# STM32H747xx_CM7 register map
File version: 1.0
Registers are 32-bit, read-write, reset 0x0 unless marked. A register's access mark holds for its fields unless they carry their own. Offsets are from the block's base; [hi:lo] are bit positions; {n}, {i} and the like mark numbered series; 'fields as' and 'values as' point back to an identical list.

## VREFBUF
Base 0x58003C00
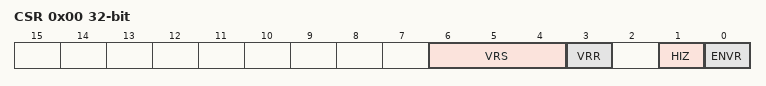
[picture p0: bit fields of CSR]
0x00 CSR — VREFBUF control and status register
  [6:4] VRS — Voltage reference scale
  [3] VRR — Voltage reference buffer ready
  [1] HIZ — High impedance mode
  [0] ENVR — Voltage reference buffer enable
0x04 CCR — VREFBUF calibration and control register
  [5:0] TRIM — TRIM[5:0] bits (Trimming code)

## IWDG1 — Independent WATCHDOG
Base 0x58004800
Same registers: IWDG2 0x58004C00
0x00 KR — IWDG Key register
  [15:0] KEY — Key value (write only, read 0000h)
0x04 PR — IWDG Prescaler register
  [2:0] PR — PR[2:0] (Prescaler divider)
0x08 RLR — IWDG Reload register
  [11:0] RL — Watchdog counter reload value
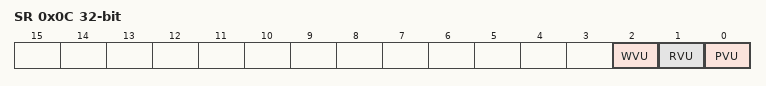
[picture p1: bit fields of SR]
0x0C SR — IWDG Status register
  [2] WVU — Watchdog counter window value update
  [1] RVU — Watchdog counter reload value update
  [0] PVU — Watchdog prescaler value update
0x10 WINR — IWDG Window register
  [11:0] WIN — Watchdog counter window value

## GPIOA — General Purpose I/O
Base 0x58020000
Same registers: GPIOB 0x58020400, GPIOC 0x58020800, GPIOD 0x58020C00, GPIOE 0x58021000, GPIOF 0x58021400, GPIOG 0x58021800, GPIOH 0x58021C00, GPIOI 0x58022000, GPIOJ 0x58022400, GPIOK 0x58022800
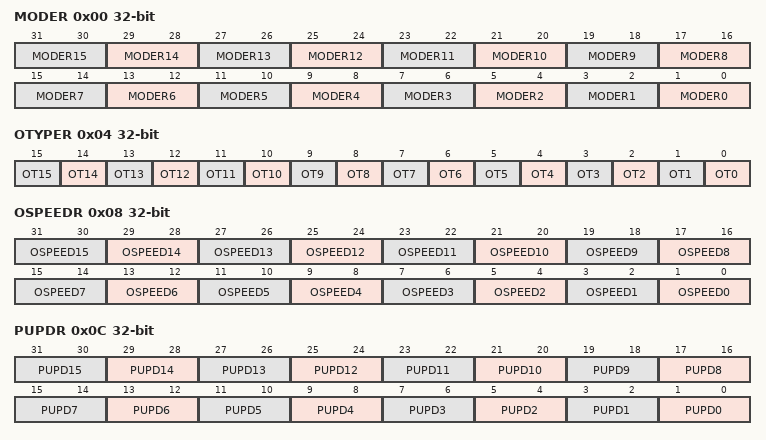
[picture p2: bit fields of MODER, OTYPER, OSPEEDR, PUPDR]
0x00 MODER — GPIO port mode register
  [2n+1:2n] MODER{n} (n=0..15)
0x04 OTYPER — GPIO port output type register
  [n] OT{n} (n=0..15)
0x08 OSPEEDR — GPIO port output speed register
  [2n+1:2n] OSPEED{n} (n=0..15)
0x0C PUPDR — GPIO port pull-up/pull-down register
  [2n+1:2n] PUPD{n} (n=0..15)
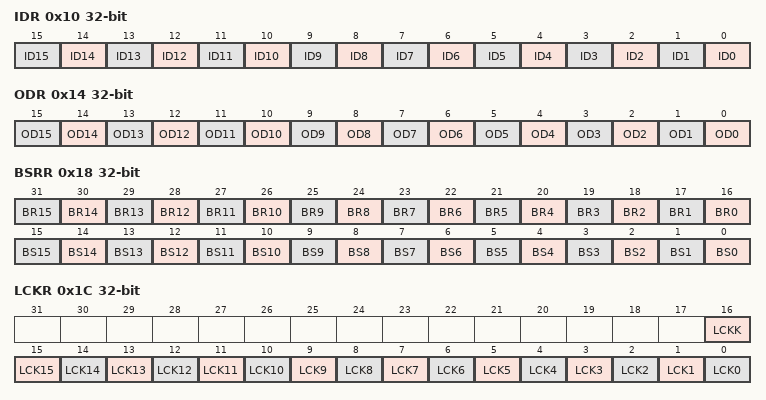
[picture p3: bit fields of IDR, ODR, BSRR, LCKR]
0x10 IDR — GPIO port input data register
  [n] ID{n} (n=0..15)
0x14 ODR — GPIO port output data register
  [n] OD{n} (n=0..15)
0x18 BSRR — GPIO port bit set/reset
  [n+16] BR{n} (n=0..15), [n] BS{n} (n=0..15)
0x1C LCKR — GPIO port configuration lock register
  [16] LCKK, [n] LCK{n} (n=0..15)
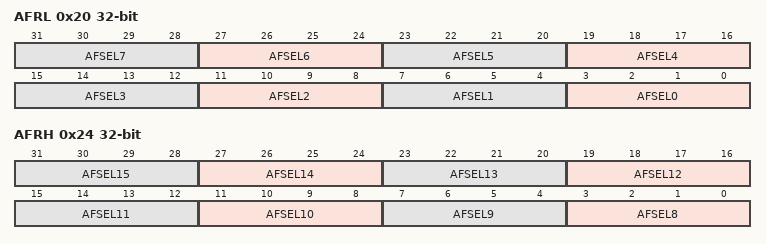
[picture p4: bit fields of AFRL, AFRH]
0x20 AFRL — GPIO alternate function registers
  [4n+3:4n] AFSEL{n} (n=0..7)
0x24 AFRH — GPIO alternate function registers
  [4n-29:4n-32] AFSEL{n} (n=8..15)

## CRC — CRC calculation unit
Base 0x58024C00
0x00 DR — CRC Data register
  [31:0] DR — Data register bits
0x04 IDR — CRC Independent data register
  [31:0] IDR — General-purpose 32-bit data register bits
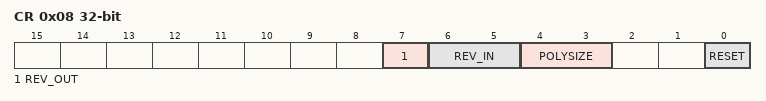
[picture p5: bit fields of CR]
0x08 CR — CRC Control register
  [7] REV_OUT — REV_OUT Reverse Output Data bits
    0=NONE (Output Data bit order not affected); 1=BIT (Output Data bit reversal done by bit)
  [6:5] REV_IN — REV_IN Reverse Input Data bits
    0=NONE (Input Data bit order not affected); 1=BYTE (Input Data bit reversal done by byte); 2=HALFWORD (Input Data bit reversal done by half-word); 3=WORD (Input Data bit reversal done by word)
  [4:3] POLYSIZE — Polynomial size bits
    0=POLYLENGTH_32B (32 bits Polynomial size); 1=POLYLENGTH_16B (16 bits Polynomial size); 2=POLYLENGTH_8B (8 bits Polynomial size); 3=POLYLENGTH_7B (7 bits Polynomial size)
  [0] RESET — RESET the CRC computation unit bit
0x10 INIT — Initial CRC value register
  [31:0] INIT — Initial CRC value bits
0x14 POL — CRC polynomial register
  [31:0] POL — Coefficients of the polynomial

## BDMA
Base 0x58025400
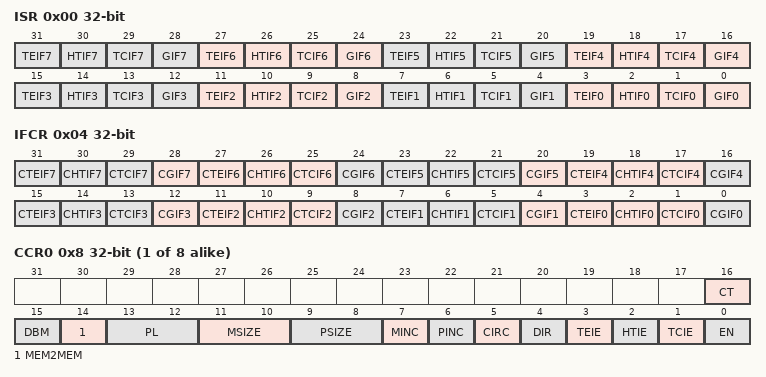
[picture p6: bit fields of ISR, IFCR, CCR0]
0x00 ISR — DMA interrupt status register
  [4n+3] TEIF{n} (n=0..7) — Channel {n} Transfer Error flag
  [4n+2] HTIF{n} (n=0..7) — Channel {n} Half Transfer flag
  [4n+1] TCIF{n} (n=0..7) — Channel {n} Transfer Complete flag
  [4n] GIF{n} (n=0..7) — Channel {n} Global interrupt flag
0x04 IFCR — DMA interrupt flag clear register
  [4n+3] CTEIF{n} (n=0..7) — Channel {n} Transfer Error clear
  [4n+2] CHTIF{n} (n=0..7) — Channel {n} Half Transfer clear
  [4n+1] CTCIF{n} (n=0..7) — Channel {n} Transfer Complete clear
  [4n] CGIF{n} (n=1..7) — Channel {n} Global interrupt clear
  [0] CGIF0 — Channel 0 Global interrupt clearr
{0x8+0x14*i} CCR{i} (i=0..7) — DMA channel x configuration register
  [16] CT — Memory to memory mode
  [15] DBM — Memory to memory mode
  [14] MEM2MEM — Memory to memory mode
  [13:12] PL — PL[1:0] bits(Channel Priority level)
  [11:10] MSIZE — MSIZE[1:0] bits (Memory size)
  [9:8] PSIZE — PSIZE[1:0] bits (Peripheral size)
  [7] MINC — Memory increment mode
  [6] PINC — Peripheral increment mode
  [5] CIRC — Circular mode
  [4] DIR — Data transfer direction
  [3] TEIE — Transfer error interrupt enable
  [2] HTIE — Half Transfer interrupt enable
  [1] TCIE — Transfer complete interrupt enable
  [0] EN — Channel enable
{0xC+0x14*i} CNDTR{i} (i=0..7) — DMA channel x number of data register
  [15:0] NDT — Number of data to Transfer
{0x10+0x14*i} CPAR{i} (i=0..7) — DMA channel x peripheral address register
  [31:0] PA — Peripheral Address
{0x14+0x14*i} CM0AR{i} (i=0..7) — DMA channel x memory 0 address register
  [31:0] MA — Memory Address
{0x18+0x14*i} CM1AR{i} (i=0..7) — DMA channel x memory 1 address register
  [31:0] MA — Memory Address

## HSEM — HW Semaphore HSEM
Base 0x58026400
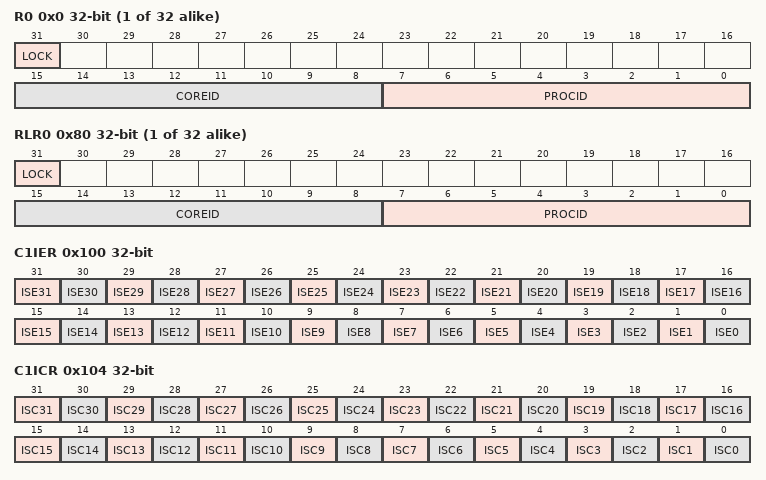
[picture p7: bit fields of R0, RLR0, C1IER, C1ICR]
{0x0+4i} R{i} (i=0..31) — 2-step write lock and read back registers
  [31] LOCK — Lock indication
  [15:8] COREID — Semaphore CoreID
    0=NONE; 3=CPU1; 1=CPU2
  [7:0] PROCID — Semaphore ProcessID
{0x80+4i} RLR{i} (i=0..31) — 1-step read lock registers
  [31] LOCK — Lock indication
  [15:8] COREID — Semaphore CoreID
  [7:0] PROCID — Semaphore ProcessID
0x100 C1IER — HSEM Interrupt 0 enable register
  [n] ISE{n} (n=5..31) — semaphore {n} interrupt 0 enable bit
  [n] ISE{n} (n=0..4) — semaphore {n} , interrupt 0 enable bit
0x104 C1ICR — HSEM Interrupt 0 clear register
  [n] ISC{n} (n=5..31) — semaphore {n} interrupt 0 clear bit
  [n] ISC{n} (n=0..4) — semaphore {n} , interrupt 0 clear bit
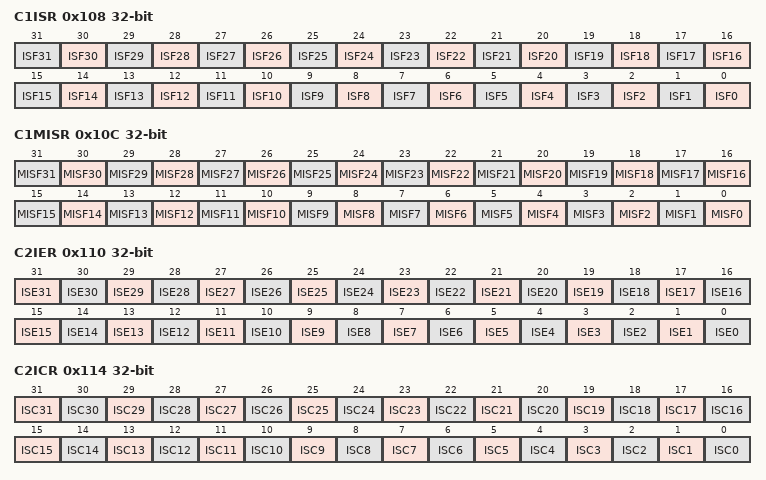
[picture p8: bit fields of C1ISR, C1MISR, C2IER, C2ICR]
0x108 C1ISR — HSEM Interrupt 0 Status register
  [n] ISF{n} (n=0..31) — semaphore {n} interrupt 0 status bit
0x10C C1MISR — HSEM Interrupt 0 Masked Status register
  [n] MISF{n} (n=0..31) — semaphore {n} interrupt 0 masked status bit
0x110 C2IER — HSEM Interrupt 1 enable register
  [n] ISE{n} (n=5..31) — semaphore {n} interrupt 1 enable bit
  [n] ISE{n} (n=0..4) — semaphore {n} , interrupt 1 enable bit
0x114 C2ICR — HSEM Interrupt 1 clear register
  [n] ISC{n} (n=5..31) — semaphore {n} interrupt 1 clear bit
  [n] ISC{n} (n=0..4) — semaphore {n} , interrupt 1 clear bit
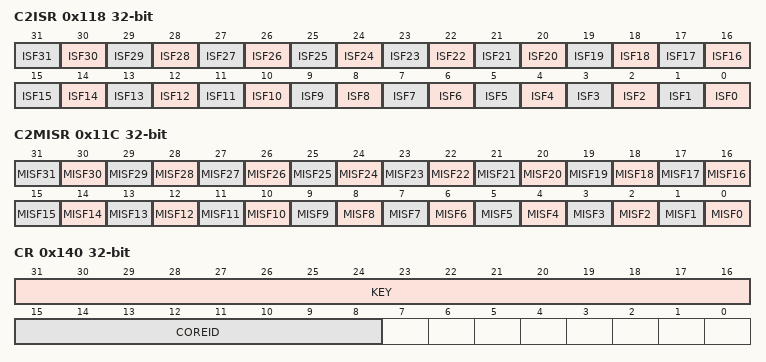
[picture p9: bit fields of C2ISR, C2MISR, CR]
0x118 C2ISR — HSEM Interrupt 1 Status register
  [n] ISF{n} (n=0..31) — semaphore {n} interrupt 1 status bit
0x11C C2MISR — HSEM Interrupt 1 Masked Status register
  [n] MISF{n} (n=0..31) — semaphore {n} interrupt 1 masked status bit
0x140 CR — HSEM Semaphore clear register
  [31:16] KEY — semaphores clear key
  [15:8] COREID — CoreID of semaphores to be cleared
0x144 KEYR — HSEM Semaphore clear key register
  [31:16] KEY — semaphores clear key

## DBGMCU — Debug MCU
Base 0x5C001000
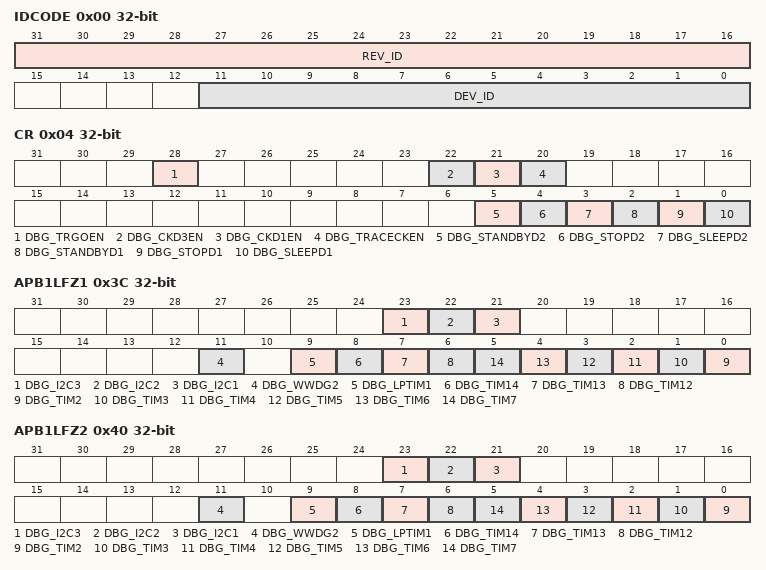
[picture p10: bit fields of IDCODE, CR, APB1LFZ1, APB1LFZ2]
0x00 IDCODE — MCU device ID code
  [31:16] REV_ID, [11:0] DEV_ID
0x04 CR — Debug MCU configuration register
  [28] DBG_TRGOEN
    0=INPUT_DIRECTION; 1=OUTPUT_DIRECTION
  [22] DBG_CKD3EN
  [21] DBG_CKD1EN
  [20] DBG_TRACECKEN
  [5] DBG_STANDBYD2
  [4] DBG_STOPD2
  [3] DBG_SLEEPD2
  [2] DBG_STANDBYD1
  [1] DBG_STOPD1
  [0] DBG_SLEEPD1
0x34 APB3FZ1 — Debug MCU APB3FZ1 freeze register
  [6] DBG_WWDG1
0x38 APB3FZ2 — Debug MCU APB3FZ2 freeze register
  [6] DBG_WWDG1
0x3C APB1LFZ1 — Debug MCU APB1LFZ1 freeze register
  [23] DBG_I2C3, [22] DBG_I2C2, [21] DBG_I2C1, [11] DBG_WWDG2, [9] DBG_LPTIM1, [8] DBG_TIM14, [7] DBG_TIM13, [6] DBG_TIM12, [n-2] DBG_TIM{n} (n=2..7)
0x40 APB1LFZ2 — Debug MCU APB1LFZ2 freeze register
  fields as APB1LFZ1
0x44 APB1HFZ1 — Debug MCU APB1LFZ1 freeze register
  [8] DBG_FDCAN
0x48 APB1HFZ2 — Debug MCU APB1LFZ2 freeze register
  [8] DBG_FDCAN
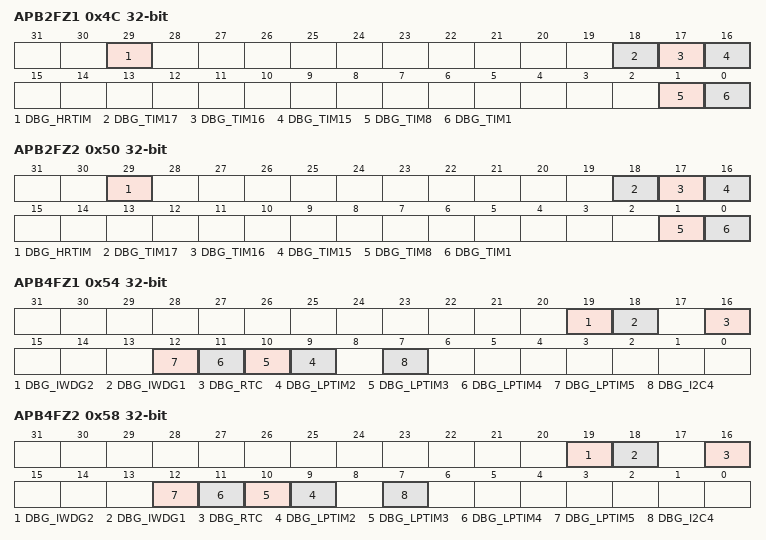
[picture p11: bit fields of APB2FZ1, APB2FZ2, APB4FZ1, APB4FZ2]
0x4C APB2FZ1 — Debug MCU APB2FZ1 freeze register
  [29] DBG_HRTIM, [18] DBG_TIM17, [17] DBG_TIM16, [16] DBG_TIM15, [1] DBG_TIM8, [0] DBG_TIM1
0x50 APB2FZ2 — Debug MCU APB2FZ2 freeze register
  fields as APB2FZ1
0x54 APB4FZ1 — Debug MCU APB4FZ1 freeze register
  [19] DBG_IWDG2, [18] DBG_IWDG1, [16] DBG_RTC, [n+7] DBG_LPTIM{n} (n=2..5), [7] DBG_I2C4
0x58 APB4FZ2 — Debug MCU APB4FZ2 freeze register
  fields as APB4FZ1
